# GD32H71x_72x register map
File version: 1.0
CPU: CM7 r1p2, little endian, MPU, FPU, 4 interrupt priority bits
Registers are 32-bit, read-write, reset 0x0 unless marked. A register's access mark holds for its fields unless they carry their own. Offsets are from the block's base; [hi:lo] are bit positions; {n}, {i} and the like mark numbered series.

## CAN_SYSCFG — Controller area network system configuration
Base 0x4001A800
0x00 CAN_MRAM ro — MRAM initialization register
  [0] IRF — CAN share message SRAM initialization finish
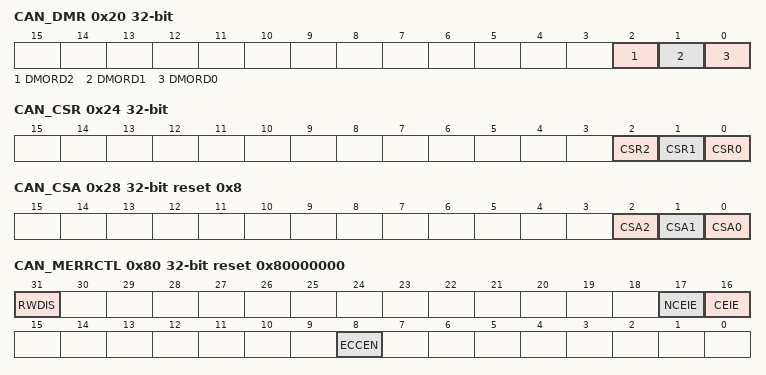
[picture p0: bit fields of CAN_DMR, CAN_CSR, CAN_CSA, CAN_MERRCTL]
0x20 CAN_DMR — Disable modification on read register
  [2] DMORD2 — disable modification on read function enable for M_CAN of the third DTM_CAN in the CAN cluster
  [1] DMORD1 — disable modification on read function enable for M_CAN of the second DTM_CAN in the CAN cluster
  [0] DMORD0 — disable modification on read function enable for M_CAN of the first DTM_CAN in the CAN cluster
0x24 CAN_CSR — Clock stop request register
  [2] CSR2 — Clock stop request signal for M_CAN of the third DTM_CAN in the CAN cluster
  [1] CSR1 — Clock stop request signal for M_CAN of the second DTM_CAN in the CAN cluster
  [0] CSR0 — Clock stop request signal for M_CAN of the first DTM_CAN in the CAN cluster
0x28 CAN_CSA ro reset 0x8 — Clock stop acknowledge register
  [2] CSA2 — Clock stop acknowledge for M_CAN of the third DTM_CAN in the CAN cluster
  [1] CSA1 — Clock stop acknowledge for M_CAN of the second DTM_CAN in the CAN cluster
  [0] CSA0 — Clock stop acknowledge for M_CAN of the first DTM_CAN in the CAN cluster
0x70 CAN_CTL — Control register
  [29] ECRWEN — CAN_MERRCTL register write access enable
0x80 CAN_MERRCTL reset 0x80000000 — Memory error control register
  [31] RWDIS — CAN_MERRCTL register write access disable
  [17] NCEIE — Noncorrectable error interrupt enable
  [16] CEIE — Correctable error interrupt enable
  [8] ECCEN — Enable ECC
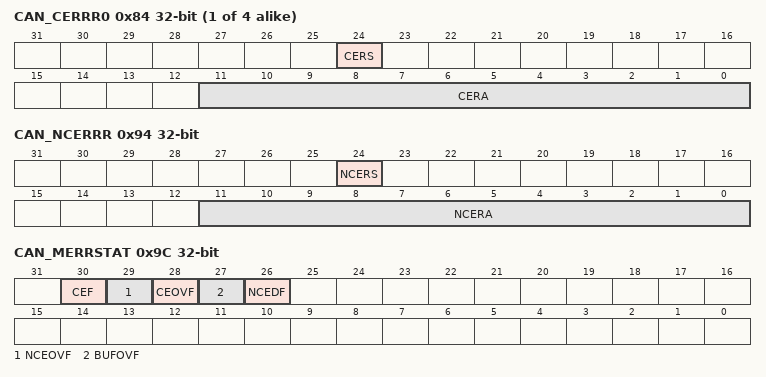
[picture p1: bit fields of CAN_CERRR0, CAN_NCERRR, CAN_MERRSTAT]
{0x84+4i} CAN_CERRR{i} access per field (i=0..3) — Correctable error record register {i}
  [24] CERS rw — Correctable error record status
  [11:0] CERA ro — Correctable error record address
0x94 CAN_NCERRR access per field — Noncorrectable error record register
  [24] NCERS rw — Noncorrectable error record status
  [11:0] NCERA ro — Noncorrectable error record address
0x9C CAN_MERRSTAT — Memory error status register
  [30] CEF — Correctable error flag
  [29] NCEOVF — Noncorrectable error overflow flag
  [28] CEOVF — Correctable error overflow flag
  [27] BUFOVF — Correctable error record buffer overflow flag
  [26] NCEDF — Noncorrectable double bit error flag

## CAU — Cryptographic acceleration unit
Base 0x48021000
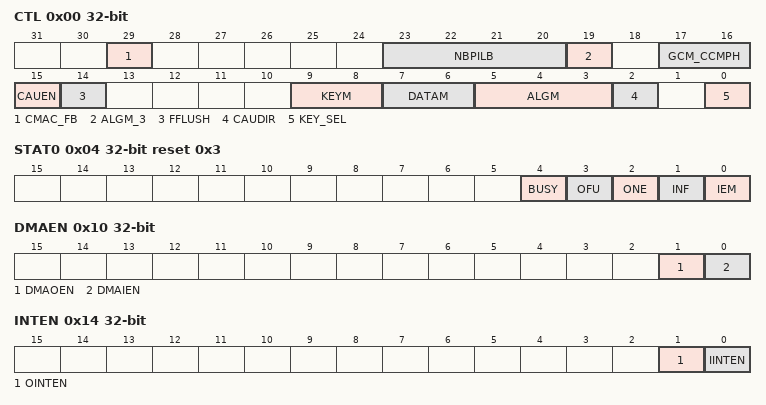
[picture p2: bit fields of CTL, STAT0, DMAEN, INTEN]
0x00 CTL access per field — CAU control register
  [29] CMAC_FB rw — CMAC generate mac final block control
  [23:20] NBPILB rw — Number of bytes padding in last block of payload
  [19] ALGM_3 rw — Encryption/decryption algorithm mode bit 3
  [17:16] GCM_CCMPH rw — GCM CCM phase
  [15] CAUEN rw — Cryptographic module enable
  [14] FFLUSH wo — FIFO flush
  [9:8] KEYM rw — AES key size mode configuration
  [7:6] DATAM rw — Data swapping type mode configuration
  [5:3] ALGM rw — Encryption/decryption algorithm mode
  [2] CAUDIR rw — CAU direction
  [0] KEY_SEL rw — Key select
0x04 STAT0 ro reset 0x3 — CAU status register 0
  [4] BUSY — BUSY flag
  [3] OFU — OUT FIFO full flag
  [2] ONE — OUT FIFO not empty flag
  [1] INF — IN FIFO not full flag
  [0] IEM — IN FIFO empty flag
0x08 DI — CAU data input register
  [31:0] DI — Data input
0x0C DO ro — CAU data output register
  [31:0] DO — Data output
0x10 DMAEN — CAU DMA enable register
  [1] DMAOEN — Out FIFO DMA enable
  [0] DMAIEN — In FIFO DMA enable
0x14 INTEN — CAU interrupt enable register
  [1] OINTEN — Out FIFO interrupt enable
  [0] IINTEN — In FIFO interrupt enable
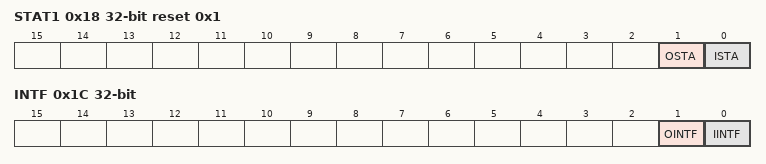
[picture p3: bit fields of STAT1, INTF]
0x18 STAT1 ro reset 0x1 — CAU interrupt status flag register 1
  [1] OSTA — Out FIFO interrupt flag
  [0] ISTA — In FIFO interrupt flag
0x1C INTF ro — CAU enable interrupt status flag register
  [1] OINTF — Out FIFO enabled interrupt flag
  [0] IINTF — In FIFO enabled interrupt flag
{0x20+8i} KEY{i}H wo (i=0..3) — CAU key register
  [31:0] KEY{i}H — Key for DES,TDES,AES
{0x24+8i} KEY{i}L wo (i=0..3) — CAU key register
  [31:0] KEY{i}L — Key for DES,TDES,AES
0x40 IV0H — CAU initialization register
  [31:0] IV0H — The initialization vector for DES,TDES,AES
0x44 IV0L — CAU initialization register
  [31:0] IV0L — The initialization vector for DES,TDES,AES
0x48 IV1H — CAU initialization register
  [31:0] IV1H — The initialization vector for DES,TDES,AES
0x4C IV1L — CAU initialization register
  [31:0] IV1L — The initialization vector for DES,TDES,AES
{0x50+4i} GCMCCMCTXS{i} (i=0..7) — GCM or CCM mode context switch register {i}
  [31:0] CTX{i} — The internal status of the CAU core
{0x70+4i} GCMCTXS{i} (i=0..7) — GCM mode context switch register {i}
  [31:0] CTX{i} — The internal status of the CAU core
{0x90+4i} CMACCTXS{i} (i=0..3) — CMAC mode context switch register {i}
  [31:0] CTX{i} — The internal status of the CAU core
0x100 ERROR_FLAG
  [0] KEY_ERROR_FLAG
